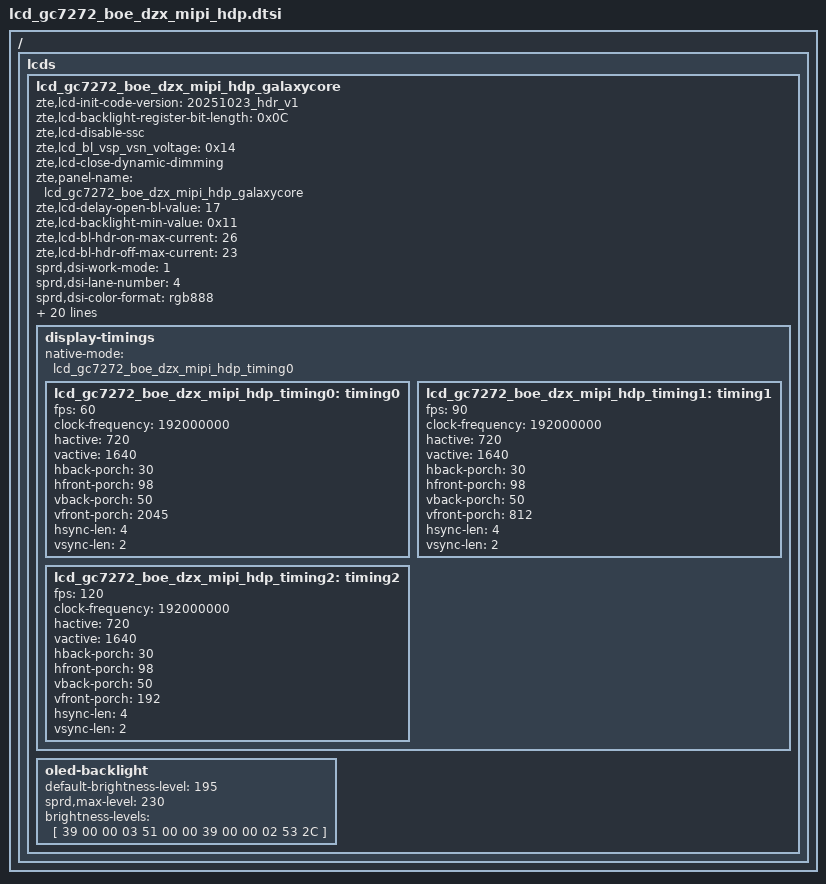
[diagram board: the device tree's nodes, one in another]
/ {
	fragment {
		target-path = "/";
		__overlay__ {
			lcds {
				lcd_gc7272_boe_dzx_mipi_hdp_galaxycore:lcd_gc7272_boe_dzx_mipi_hdp_galaxycore {
					zte,lcd-init-code-version = "20251023_hdr_v1";
					zte,lcd-backlight-register-bit-length = <0x0C>;
					zte,lcd-disable-ssc;
					zte,lcd_bl_vsp_vsn_voltage = <0x14>;
					zte,lcd-close-dynamic-dimming;
					zte,panel-name = "lcd_gc7272_boe_dzx_mipi_hdp_galaxycore";
					zte,lcd-delay-open-bl-value = <17>;
					zte,lcd-backlight-min-value = <0x11>;
					zte,lcd-bl-hdr-on-max-current = <26>;
					zte,lcd-bl-hdr-off-max-current = <23>;

					sprd,dsi-work-mode = <1>; /* video burst mode*/
					sprd,dsi-lane-number = <4>;
					sprd,dsi-color-format = "rgb888";
					sprd,vrr-enabled;

					sprd,phy-bit-clock = <1382000>;	/* kbps */
					sprd,phy-escape-clock = <20000>;/* kHz */

					//sprd,dpi-clk-div = <6>;
					//sprd,video-lp-cmd-enable = <1>;
					//sprd,hporch-lp-disable = <1>;
					sprd,width-mm = <7026>;/*zte mod for 6.88*/
					sprd,height-mm = <16005>;/*zte mod for 6.88*/
					sprd,esd-check-enable = <1>;
					sprd,esd-check-mode = <1>;
					//sprd,esd-check-register = <0xA>;
					//sprd,esd-check-value = <0x9C>;
					sprd,esd-check-period = <2000>;

					sprd,reset-on-sequence = <1 5>, <0 5>, <1 5>, <0 5>, <1 5>, <0 5>, <1 10>, <0 10>, <1 25>;
					sprd,reset-off-sequence = <1 20>;

					sprd,use-dcs-write;
					sprd,initial-command = [
						39 00 00 04 FF 55 AA 66
						23 00 00 02 FF 10
						23 00 00 02 FB 00
						23 00 00 02 FF 20
						23 00 00 02 FB 00
						23 00 00 02 FF 21
						23 00 00 02 FB 00
						23 00 00 02 FF 22
						23 00 00 02 FB 00
						23 00 00 02 FF 23
						23 00 00 02 FB 00
						23 00 00 02 FF 24
						23 00 00 02 FB 00
						23 00 00 02 FF 25
						23 00 00 02 FB 00
						23 00 00 02 FF 27
						23 00 00 02 FB 00
						23 00 00 02 FF 26
						23 00 00 02 FB 00
						23 00 00 02 FF 28
						23 00 00 02 FB 00
						23 00 00 02 FF A3
						23 00 00 02 FB 00
						23 00 00 02 FF B3
						23 00 00 02 FB 00
						23 00 00 02 FF 20
						23 00 00 02 2D 55
						23 00 00 02 AB 16
						23 00 00 02 AF 16
						23 00 00 02 FF B3
						23 00 00 02 4E 46
						23 00 00 02 3F 77
						23 00 00 02 50 10
						23 00 00 02 47 01
						23 00 00 02 FF 20
						23 00 00 02 29 E0
						23 00 00 02 20 84
						23 00 00 02 21 00
						23 00 00 02 22 80
						23 00 00 02 2E 00
						23 00 00 02 FF A3
						23 00 00 02 58 AA
						23 00 00 02 FF 26
						23 00 00 02 43 00
						23 00 00 02 FF 22
						23 00 00 02 0E 33
						23 00 00 02 0C 01
						23 00 00 02 0B 56
						23 00 00 02 0D 02
						23 00 00 02 FF B3
						23 00 00 02 42 05
						23 00 00 02 44 52
						23 00 00 02 FF 28
						23 00 00 02 7D 1F
						23 00 00 02 7B 40

						23 00 00 02 FF 22
						23 00 00 02 E4 00
						23 00 00 02 01 06
						23 00 00 02 02 68
						23 00 00 02 03 00
						23 00 00 02 FF 20
						23 00 00 02 C7 00
						23 00 00 02 C8 78
						23 00 00 02 C9 00
						23 00 00 02 CA 78
						23 00 00 02 B7 00
						23 00 00 02 B8 1E
						23 00 00 02 B9 01
						23 00 00 02 BA 2C
						23 00 00 02 D4 19
						23 00 00 02 FF 22
						23 00 00 02 83 07
						23 00 00 02 84 00
						23 00 00 02 8B 01
						23 00 00 02 8C 00
						23 00 00 02 93 09
						23 00 00 02 94 00
						23 00 00 02 9B D5
						23 00 00 02 9C 00
						23 00 00 02 FF 28
						23 00 00 02 01 25
						23 00 00 02 02 1A
						23 00 00 02 03 1E
						23 00 00 02 04 00
						23 00 00 02 05 02
						23 00 00 02 06 08
						23 00 00 02 07 0A
						23 00 00 02 08 0C
						23 00 00 02 09 0E
						23 00 00 02 0A 10
						23 00 00 02 0B 12
						23 00 00 02 0C 14
						23 00 00 02 0D 16
						23 00 00 02 0E 1F
						23 00 00 02 0F 25
						23 00 00 02 10 25
						23 00 00 02 11 25
						23 00 00 02 12 25
						23 00 00 02 13 25
						23 00 00 02 14 25
						23 00 00 02 15 25
						23 00 00 02 16 25
						23 00 00 02 17 25
						23 00 00 02 18 1A
						23 00 00 02 19 1E
						23 00 00 02 1A 01
						23 00 00 02 1B 03
						23 00 00 02 1C 09
						23 00 00 02 1D 0B
						23 00 00 02 1E 0D
						23 00 00 02 1F 0F
						23 00 00 02 20 11
						23 00 00 02 21 13
						23 00 00 02 22 15
						23 00 00 02 23 17
						23 00 00 02 24 1F
						23 00 00 02 25 25
						23 00 00 02 26 25
						23 00 00 02 27 25
						23 00 00 02 28 25
						23 00 00 02 29 25
						23 00 00 02 2A 25
						23 00 00 02 2B 25
						23 00 00 02 2D 25
						23 00 00 02 30 00
						23 00 00 02 31 00
						23 00 00 02 34 00
						23 00 00 02 35 00
						23 00 00 02 36 01
						23 00 00 02 37 00
						23 00 00 02 38 00
						23 00 00 02 39 00
						23 00 00 02 2F 40

						23 00 00 02 FF 21
						23 00 00 02 7E 0F
						23 00 00 02 7F 26
						23 00 00 02 8B 26
						23 00 00 02 97 26
						23 00 00 02 A3 26
						23 00 00 02 80 06
						23 00 00 02 8C 02
						23 00 00 02 98 0E
						23 00 00 02 A4 0A
						23 00 00 02 AF 40
						23 00 00 02 B0 40
						23 00 00 02 B1 40
						23 00 00 02 B2 40
						23 00 00 02 83 07
						23 00 00 02 8F 07
						23 00 00 02 9B 07
						23 00 00 02 A7 07
						23 00 00 02 D2 64
						23 00 00 02 D4 64
						23 00 00 02 D6 64
						23 00 00 02 D8 64
						23 00 00 02 D3 6A
						23 00 00 02 D5 6A
						23 00 00 02 D7 6A
						23 00 00 02 D9 6A
						23 00 00 02 87 22
						23 00 00 02 93 02
						23 00 00 02 9F 06
						23 00 00 02 AB 0A
						23 00 00 02 82 A0
						23 00 00 02 8E A0
						23 00 00 02 9A A0
						23 00 00 02 A6 A0
						23 00 00 02 2B 00
						23 00 00 02 2E 00
						23 00 00 02 88 80
						23 00 00 02 89 00
						23 00 00 02 8A 00
						23 00 00 02 94 80
						23 00 00 02 95 00
						23 00 00 02 96 00
						23 00 00 02 A0 80
						23 00 00 02 A1 00
						23 00 00 02 A2 00
						23 00 00 02 AC 80
						23 00 00 02 AD 00
						23 00 00 02 AE 00
						23 00 00 02 45 0F
						23 00 00 02 46 A8
						23 00 00 02 4C A8
						23 00 00 02 52 A8
						23 00 00 02 58 A8
						23 00 00 02 47 14
						23 00 00 02 4D 13
						23 00 00 02 53 10
						23 00 00 02 59 0F
						23 00 00 02 76 40
						23 00 00 02 77 40
						23 00 00 02 78 40
						23 00 00 02 79 40
						23 00 00 02 E7 6A
						23 00 00 02 E8 6A
						23 00 00 02 E9 6A
						23 00 00 02 EA 6A
						23 00 00 02 EB 6A
						23 00 00 02 EC 6A
						23 00 00 02 ED 6A
						23 00 00 02 EE 6A
						23 00 00 02 B3 E1
						23 00 00 02 B4 14
						23 00 00 02 B7 E1
						23 00 00 02 B8 14
						23 00 00 02 BC 54
						23 00 00 02 BD 4C
						23 00 00 02 BB AA
						23 00 00 02 C2 8A
						23 00 00 02 C6 42
						23 00 00 02 29 00
						23 00 00 02 18 00
						23 00 00 02 FF 22
						23 00 00 02 05 00
						23 00 00 02 08 22

						23 00 00 02 FF 28
						23 00 00 02 3D 46
						23 00 00 02 3E 46
						23 00 00 02 3F 55
						23 00 00 02 40 55
						23 00 00 02 45 46
						23 00 00 02 46 46
						23 00 00 02 47 5A
						23 00 00 02 48 5A
						23 00 00 02 4D A2
						23 00 00 02 50 2A
						23 00 00 02 75 22
						23 00 00 02 52 72
						23 00 00 02 77 22
						23 00 00 02 79 02
						23 00 00 02 57 20
						23 00 00 02 5A 9b
						23 00 00 02 5B A7
						23 00 00 02 FF 20
						23 00 00 02 7E 01
						23 00 00 02 70 32
						23 00 00 02 71 00
						23 00 00 02 72 64
						23 00 00 02 73 00
						23 00 00 02 74 00
						23 00 00 02 75 64
						23 00 00 02 76 64
						23 00 00 02 77 30
						23 00 00 02 78 CF
						23 00 00 02 79 30
						23 00 00 02 7A CF
						23 00 00 02 7C 31
						23 00 00 02 7D 31
						23 00 00 02 FF 25
						23 00 00 02 75 00
						23 00 00 02 85 36
						23 00 00 02 86 00
						23 00 00 02 87 64
						23 00 00 02 88 00
						23 00 00 02 89 64
						23 00 00 02 8A 64
						23 00 00 02 8B 64
						23 00 00 02 8C 17
						23 00 00 02 8D C1
						23 00 00 02 8E 17
						23 00 00 02 8F C1
						23 00 00 02 91 18
						23 00 00 02 92 18
						23 00 00 02 FF 23
						23 00 00 02 29 03
						23 00 00 02 EF 02
						39 00 00 11 01 00 26 00 29 00 4A 00 64 00 77 00 8D 00 9A 00 AB
						39 00 00 11 02 00 B6 00 E3 01 05 01 3A 01 63 01 A3 01 DD 01 DF
						39 00 00 11 03 02 1E 02 6A 02 9A 02 DC 03 07 03 42 03 54 03 62
						39 00 00 0D 04 03 76 03 90 03 A4 03 CA 03 E7 03 FF
						39 00 00 11 0D 00 26 00 29 00 4A 00 64 00 77 00 8D 00 9A 00 AB
						39 00 00 11 0E 00 B6 00 E3 01 05 01 3A 01 63 01 A3 01 DD 01 DF
						39 00 00 11 0F 02 1E 02 6A 02 9A 02 DC 03 07 03 42 03 54 03 62
						39 00 00 0D 10 03 76 03 90 03 A4 03 CA 03 E7 03 FF
						23 00 00 02 F0 01
						23 00 00 02 2B 42
						23 00 00 02 2D 65
						23 00 00 02 2E 00
						23 00 00 02 32 04
						23 00 00 02 33 21
						23 00 00 02 FF 20
						23 00 00 02 15 13
						23 00 00 02 16 88
						23 00 00 02 17 0F
						23 00 00 02 18 A0
						23 00 00 02 19 0A
						23 00 00 02 1A 28
						23 00 00 02 1B 07
						23 00 00 02 1C D0
						23 00 00 02 FF 10
						39 00 00 03 51 00 00
						23 00 00 02 53 2c
						23 00 00 02 55 00
						23 00 00 02 36 08
						23 00 00 02 69 01
						23 00 00 02 35 00
						23 00 00 02 BA 03
						23 64 00 02 11 00
						23 0A 00 02 29 00
					];

					sprd,sleep-in-command = [
						39 00 00 04 FF 55 AA 66
						23 00 00 02 FF 10
						23 32 00 02 28 00
						23 78 00 02 10 00
						23 14 00 02 4F 01
					];

					sprd,sleep-in-command2 = [
						39 00 00 04 FF 55 AA 66
						23 00 00 02 FF 10
						23 00 00 02 EB 04
						23 32 00 02 28 00
						23 78 00 02 10 00
					];

					sprd,sleep-out-command = [
						13 78 00 01 11
						13 64 00 01 29
					];

					display-timings {
						native-mode = <&lcd_gc7272_boe_dzx_mipi_hdp_timing0>;
						lcd_gc7272_boe_dzx_mipi_hdp_timing0: timing0 {
							fps = <60>;
							clock-frequency = <192000000>;
							hactive = <720>;
							vactive = <1640>;
							hback-porch = <30>;
							hfront-porch = <98>;
							vback-porch = <50>;
							vfront-porch = <2045>;
							hsync-len = <4>;
							vsync-len = <2>;
						};
						lcd_gc7272_boe_dzx_mipi_hdp_timing1: timing1 {
							fps = <90>;
							clock-frequency = <192000000>;
							hactive = <720>;
							vactive = <1640>;
							hback-porch = <30>;
							hfront-porch = <98>;
							vback-porch = <50>;
							vfront-porch = <812>;
							hsync-len = <4>;
							vsync-len = <2>;
						};
						lcd_gc7272_boe_dzx_mipi_hdp_timing2: timing2 {
							fps = <120>;
							clock-frequency = <192000000>;
							hactive = <720>;
							vactive = <1640>;
							hback-porch = <30>;
							hfront-porch = <98>;
							vback-porch = <50>;
							vfront-porch = <192>;
							hsync-len = <4>;
							vsync-len = <2>;
							};
					};
					oled-backlight {
						default-brightness-level = <195>;
						sprd,max-level = <230>;
						brightness-levels = [
							39 00 00 03 51 00 00
							39 00 00 02 53 2C
						];
					};
				};
			};
		};
	};
};

